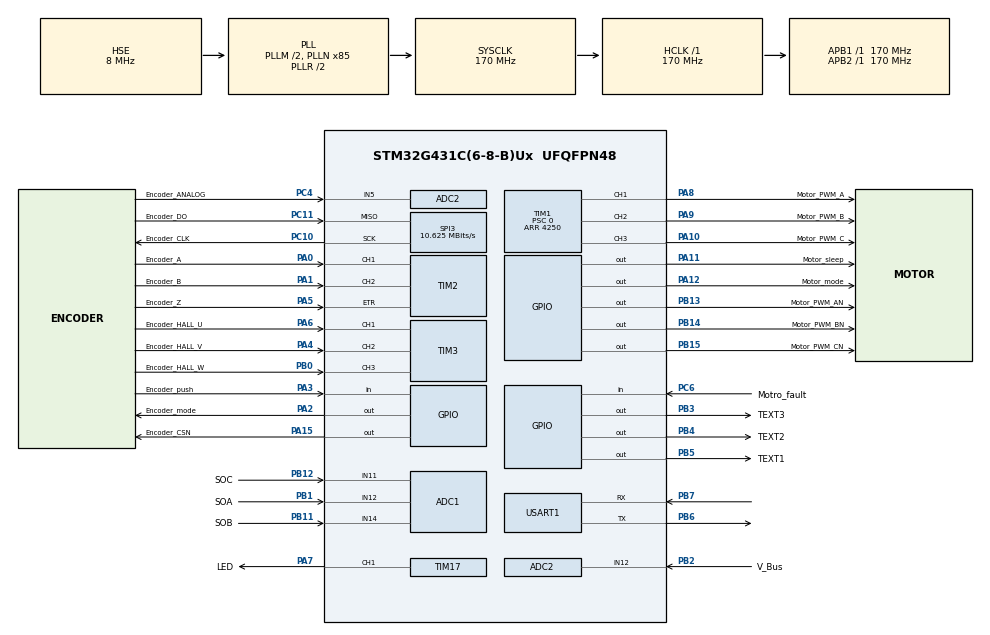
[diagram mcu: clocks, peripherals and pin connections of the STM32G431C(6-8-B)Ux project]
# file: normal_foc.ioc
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ADC1.EnableInjectedConversion=ENABLE
ADC1.EnableRegularConversion=DISABLE
ADC1.ExternalTrigInjecConv=ADC_EXTERNALTRIGINJEC_T1_CC4
ADC1.InjNumberOfConversion=3
ADC1.InjectedChannel-6\#ChannelInjectedConversion=ADC_CHANNEL_12
ADC1.InjectedChannel-7\#ChannelInjectedConversion=ADC_CHANNEL_14
ADC1.InjectedChannel-8\#ChannelInjectedConversion=ADC_CHANNEL_11
ADC1.InjectedOffsetNumber-6\#ChannelInjectedConversion=ADC_OFFSET_NONE
ADC1.InjectedOffsetNumber-7\#ChannelInjectedConversion=ADC_OFFSET_NONE
ADC1.InjectedOffsetNumber-8\#ChannelInjectedConversion=ADC_OFFSET_NONE
ADC1.InjectedRank-6\#ChannelInjectedConversion=1
ADC1.InjectedRank-7\#ChannelInjectedConversion=2
ADC1.InjectedRank-8\#ChannelInjectedConversion=3
ADC1.InjectedSamplingTime-6\#ChannelInjectedConversion=ADC_SAMPLETIME_6CYCLES_5
ADC1.InjectedSamplingTime-7\#ChannelInjectedConversion=ADC_SAMPLETIME_6CYCLES_5
ADC1.InjectedSamplingTime-8\#ChannelInjectedConversion=ADC_SAMPLETIME_6CYCLES_5
ADC1.Rank1_Channel=ADC_CHANNEL_12
ADC1.Rank2_Channel=ADC_CHANNEL_14
ADC1.master=1
ADC2.Channel-7\#ChannelRegularConversion=ADC_CHANNEL_5
ADC2.Channel-8\#ChannelRegularConversion=ADC_CHANNEL_12
ADC2.NbrOfConversion=2
ADC2.NbrOfConversionFlag=1
ADC2.OffsetNumber-7\#ChannelRegularConversion=ADC_OFFSET_NONE
ADC2.OffsetNumber-8\#ChannelRegularConversion=ADC_OFFSET_NONE
ADC2.Rank-7\#ChannelRegularConversion=1
ADC2.Rank-8\#ChannelRegularConversion=2
ADC2.SamplingTime-7\#ChannelRegularConversion=ADC_SAMPLETIME_12CYCLES_5
ADC2.SamplingTime-8\#ChannelRegularConversion=ADC_SAMPLETIME_12CYCLES_5
Dma.Request0=USART1_TX
Dma.Request1=SPI3_RX
Dma.SPI3_RX.1.Direction=DMA_PERIPH_TO_MEMORY
Dma.SPI3_RX.1.EventEnable=DISABLE
Dma.SPI3_RX.1.Instance=DMA1_Channel2
Dma.SPI3_RX.1.MemDataAlignment=DMA_MDATAALIGN_BYTE
Dma.SPI3_RX.1.MemInc=DMA_MINC_ENABLE
Dma.SPI3_RX.1.Mode=DMA_NORMAL
Dma.SPI3_RX.1.PeriphDataAlignment=DMA_PDATAALIGN_BYTE
Dma.SPI3_RX.1.PeriphInc=DMA_PINC_DISABLE
Dma.SPI3_RX.1.Polarity=HAL_DMAMUX_REQ_GEN_RISING
Dma.SPI3_RX.1.Priority=DMA_PRIORITY_LOW
Dma.SPI3_RX.1.RequestNumber=1
Dma.SPI3_RX.1.SignalID=NONE
Dma.SPI3_RX.1.SyncEnable=DISABLE
Dma.SPI3_RX.1.SyncPolarity=HAL_DMAMUX_SYNC_NO_EVENT
Dma.SPI3_RX.1.SyncRequestNumber=1
Dma.SPI3_RX.1.SyncSignalID=NONE
Dma.USART1_TX.0.Direction=DMA_MEMORY_TO_PERIPH
Dma.USART1_TX.0.EventEnable=DISABLE
Dma.USART1_TX.0.Instance=DMA1_Channel1
Dma.USART1_TX.0.MemDataAlignment=DMA_MDATAALIGN_BYTE
Dma.USART1_TX.0.MemInc=DMA_MINC_ENABLE
Dma.USART1_TX.0.Mode=DMA_NORMAL
Dma.USART1_TX.0.PeriphDataAlignment=DMA_PDATAALIGN_BYTE
Dma.USART1_TX.0.PeriphInc=DMA_PINC_DISABLE
Dma.USART1_TX.0.Polarity=HAL_DMAMUX_REQ_GEN_RISING
Dma.USART1_TX.0.Priority=DMA_PRIORITY_LOW
Dma.USART1_TX.0.RequestNumber=1
Dma.USART1_TX.0.SignalID=NONE
Dma.USART1_TX.0.SyncEnable=DISABLE
Dma.USART1_TX.0.SyncPolarity=HAL_DMAMUX_SYNC_NO_EVENT
Dma.USART1_TX.0.SyncRequestNumber=1
Dma.USART1_TX.0.SyncSignalID=NONE
Mcu.Family=STM32G4
Mcu.Name=STM32G431C(6-8-B)Ux
Mcu.Package=UFQFPN48
NVIC.ADC1_2_IRQn=true\:0\:0\:false\:false\:true\:true\:true\:true
NVIC.DMA1_Channel1_IRQn=true\:0\:0\:false\:false\:true\:false\:true\:true
NVIC.DMA1_Channel2_IRQn=true\:0\:0\:false\:false\:true\:false\:true\:true
NVIC.PriorityGroup=NVIC_PRIORITYGROUP_4
NVIC.TIM6_DAC_IRQn=true\:1\:0\:true\:false\:true\:true\:true\:true
NVIC.USART1_IRQn=true\:0\:0\:false\:false\:true\:true\:true\:true
PA0.GPIO_Label=Encoder_A
PA0.Signal=S_TIM2_CH1
PA1.GPIO_Label=Encoder_B
PA1.Signal=S_TIM2_CH2
PA10.GPIO_Label=Motor_PWM_C
PA10.Signal=S_TIM1_CH3
PA11.GPIO_Label=Motor_sleep
PA11.Signal=GPIO_Output
PA12.GPIO_Label=Motor_mode
PA12.Signal=GPIO_Output
PA13.Mode=Serial_Wire
PA13.Signal=SYS_JTMS-SWDIO
PA14.Mode=Serial_Wire
PA14.Signal=SYS_JTCK-SWCLK
PA15.GPIO_Label=Encoder_CSN
PA15.GPIO_PuPd=GPIO_NOPULL
PA15.Signal=GPIO_Output
PA2.GPIO_Label=Encoder_mode
PA2.Signal=GPIO_Output
PA3.GPIO_Label=Encoder_push
PA3.Signal=GPIO_Input
PA4.GPIO_Label=Encoder_HALL_V
PA4.Signal=S_TIM3_CH2
PA5.GPIO_Label=Encoder_Z
PA5.Signal=S_TIM2_ETR
PA6.GPIO_Label=Encoder_HALL_U
PA6.Signal=S_TIM3_CH1
PA7.GPIO_Label=LED
PA7.Signal=S_TIM17_CH1
PA8.GPIO_Label=Motor_PWM_A
PA8.Signal=S_TIM1_CH1
PA9.GPIO_Label=Motor_PWM_B
PA9.Signal=S_TIM1_CH2
PB0.GPIO_Label=Encoder_HALL_W
PB0.Signal=S_TIM3_CH3
PB1.GPIO_Label=SOA
PB1.Mode=IN12-Single-Ended
PB1.Signal=ADC1_IN12
PB11.GPIO_Label=SOB
PB11.Mode=IN14-Single-Ended
PB11.Signal=ADC1_IN14
PB12.GPIO_Label=SOC
PB12.Mode=IN11-Single-Ended
PB12.Signal=ADC1_IN11
PB13.GPIO_Label=Motor_PWM_AN
PB13.Signal=GPIO_Output
PB14.GPIO_Label=Motor_PWM_BN
PB14.Signal=GPIO_Output
PB15.GPIO_Label=Motor_PWM_CN
PB15.Signal=GPIO_Output
PB2.GPIO_Label=V_Bus
PB2.Mode=IN12-Single-Ended
PB2.Signal=ADC2_IN12
PB3.GPIO_Label=TEXT3
PB3.Signal=GPIO_Output
PB4.GPIO_Label=TEXT2
PB4.Signal=GPIO_Output
PB5.GPIO_Label=TEXT1
PB5.Signal=GPIO_Output
PB6.Mode=Asynchronous
PB6.Signal=USART1_TX
PB7.Mode=Asynchronous
PB7.Signal=USART1_RX
PC10.GPIO_Label=Encoder_CLK
PC10.Mode=RX_Only_Simplex_Unidirect_Master
PC10.Signal=SPI3_SCK
PC11.GPIO_Label=Encoder_DO
PC11.Mode=RX_Only_Simplex_Unidirect_Master
PC11.Signal=SPI3_MISO
PC4.GPIO_Label=Encoder_ANALOG
PC4.Mode=IN5-Single-Ended
PC4.Signal=ADC2_IN5
PC6.GPIO_Label=Motro_fault
PC6.Signal=GPIO_Input
PF0-OSC_IN.Mode=HSE-External-Oscillator
PF0-OSC_IN.Signal=RCC_OSC_IN
PF1-OSC_OUT.Mode=HSE-External-Oscillator
PF1-OSC_OUT.Signal=RCC_OSC_OUT
ProjectManager.HeapSize=0x200
ProjectManager.StackSize=0x400
ProjectManager.TargetToolchain=CMake
RCC.ADC12Freq_Value=170000000
RCC.AHBFreq_Value=170000000
RCC.APB1Freq_Value=170000000
RCC.APB1TimFreq_Value=170000000
RCC.APB2Freq_Value=170000000
RCC.APB2TimFreq_Value=170000000
RCC.CortexFreq_Value=170000000
RCC.EXTERNAL_CLOCK_VALUE=12288000
RCC.HCLKFreq_Value=170000000
RCC.HSE_VALUE=8000000
RCC.HSI48_VALUE=48000000
RCC.HSI_VALUE=16000000
RCC.LSE_VALUE=32768
RCC.PLLM=RCC_PLLM_DIV2
RCC.PLLN=85
RCC.PLLSourceVirtual=RCC_PLLSOURCE_HSE
RCC.SYSCLKFreq_VALUE=170000000
RCC.SYSCLKSource=RCC_SYSCLKSOURCE_PLLCLK
RCC.USBFreq_Value=170000000
RCC.VCOOutputFreq_Value=340000000
SH.S_TIM17_CH1.0=TIM17_CH1,PWM Generation1 CH1
SH.S_TIM1_CH1.0=TIM1_CH1,PWM Generation1 CH1
SH.S_TIM1_CH2.0=TIM1_CH2,PWM Generation2 CH2
SH.S_TIM1_CH3.0=TIM1_CH3,PWM Generation3 CH3
SH.S_TIM2_CH1.0=TIM2_CH1,Encoder_Interface_w_index
SH.S_TIM2_CH2.0=TIM2_CH2,Encoder_Interface_w_index
SH.S_TIM2_ETR.0=TIM2_ETR,Encoder_Interface_w_index
SH.S_TIM3_CH1.0=TIM3_CH1,Xored_Inputs_Hall_Sensor_Interface
SH.S_TIM3_CH2.0=TIM3_CH2,Xored_Inputs_Hall_Sensor_Interface
SH.S_TIM3_CH3.0=TIM3_CH3,Xored_Inputs_Hall_Sensor_Interface
SPI3.BaudRatePrescaler=SPI_BAUDRATEPRESCALER_16
SPI3.CLKPhase=SPI_PHASE_1EDGE
SPI3.CLKPolarity=SPI_POLARITY_HIGH
SPI3.CalculateBaudRate=10.625 MBits/s
SPI3.DataSize=SPI_DATASIZE_8BIT
SPI3.Direction=SPI_DIRECTION_2LINES_RXONLY
SPI3.Mode=SPI_MODE_MASTER
SPI3.VirtualType=VM_MASTER
STMicroelectronics.X-CUBE-ALGOBUILD.1.4.0.LibraryCcDSPOoLibraryJjDSPOoLibrary=true
TIM1.Channel-PWM\ Generation1\ CH1=TIM_CHANNEL_1
TIM1.Channel-PWM\ Generation2\ CH2=TIM_CHANNEL_2
TIM1.Channel-PWM\ Generation3\ CH3=TIM_CHANNEL_3
TIM1.Channel-PWM\ Generation4\ No\ Output=TIM_CHANNEL_4
TIM1.CounterMode=TIM_COUNTERMODE_CENTERALIGNED2
TIM1.OCMode_PWM-PWM\ Generation4\ No\ Output=TIM_OCMODE_PWM2
TIM1.PeriodNoDither=4250
TIM1.Prescaler=0
TIM17.Channel=TIM_CHANNEL_1
TIM17.PeriodNoDither=1000
TIM17.Prescaler=169
TIM2.EncoderMode=TIM_ENCODERMODE_TI12
TIM6.PeriodNoDither=1000
TIM6.Prescaler=169
USART1.VirtualMode-Asynchronous=VM_ASYNC
VP_STMicroelectronics.X-CUBE-ALGOBUILD_VS_DSPOoLibraryJjLibrary_1.4.0_1.4.0.Mode=DSPOoLibraryJjLibrary
VP_SYS_VS_DBSignals.Mode=DisableDeadBatterySignals
VP_TIM17_VS_ClockSourceINT.Mode=Enable_Timer
VP_TIM1_VS_no_output4.Mode=PWM Generation4 No Output
VP_TIM6_VS_ClockSourceINT.Mode=Enable_Timer
board=custom

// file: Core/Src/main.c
/* USER CODE BEGIN Header */
/**
  ******************************************************************************
  * @file           : main.c
  * @brief          : Main program body
  ******************************************************************************
  * @attention
  *
  * Copyright (c) 2026 STMicroelectronics.
  * All rights reserved.
  *
  * This software is licensed under terms that can be found in the LICENSE file
  * in the root directory of this software component.
  * If no LICENSE file comes with this software, it is provided AS-IS.
  *
  ******************************************************************************
  */
/* USER CODE END Header */
#include "main.h"
#include "adc.h"
#include "dma.h"
#include "spi.h"
#include "tim.h"
#include "usart.h"
#include "gpio.h"

/* USER CODE BEGIN Includes */
#include "user.h"
/* USER CODE END Includes */

void SystemClock_Config(void);

int main(void)
{

  /* MCU Configuration--------------------------------------------------------*/

  /* Reset of all peripherals, Initializes the Flash interface and the Systick. */
  HAL_Init();

  /* Configure the system clock */
  SystemClock_Config();

  /* Initialize all configured peripherals */
  MX_GPIO_Init();
  MX_DMA_Init();
  MX_ADC1_Init();
  MX_ADC2_Init();
  MX_TIM1_Init();
  MX_TIM2_Init();
  MX_TIM17_Init();
  MX_USART1_UART_Init();
  MX_TIM6_Init();
  MX_SPI3_Init();
  MX_TIM3_Init();

  /* Infinite loop */
  /* USER CODE BEGIN WHILE */
  User_Init();
  while (1)
  {
    User_Loop();
    /* USER CODE END WHILE */

  }
}

void SystemClock_Config(void)
{
  RCC_OscInitTypeDef RCC_OscInitStruct = {0};
  RCC_ClkInitTypeDef RCC_ClkInitStruct = {0};

  /** Configure the main internal regulator output voltage
  */
  HAL_PWREx_ControlVoltageScaling(PWR_REGULATOR_VOLTAGE_SCALE1_BOOST);

  /** Initializes the RCC Oscillators according to the specified parameters
  * in the RCC_OscInitTypeDef structure.
  */
  RCC_OscInitStruct.OscillatorType = RCC_OSCILLATORTYPE_HSE;
  RCC_OscInitStruct.HSEState = RCC_HSE_ON;
  RCC_OscInitStruct.PLL.PLLState = RCC_PLL_ON;
  RCC_OscInitStruct.PLL.PLLSource = RCC_PLLSOURCE_HSE;
  RCC_OscInitStruct.PLL.PLLM = RCC_PLLM_DIV2;
  RCC_OscInitStruct.PLL.PLLN = 85;
  RCC_OscInitStruct.PLL.PLLP = RCC_PLLP_DIV2;
  RCC_OscInitStruct.PLL.PLLQ = RCC_PLLQ_DIV2;
  RCC_OscInitStruct.PLL.PLLR = RCC_PLLR_DIV2;
  if (HAL_RCC_OscConfig(&RCC_OscInitStruct) != HAL_OK)
  {
    Error_Handler();
  }

  /** Initializes the CPU, AHB and APB buses clocks
  */
  RCC_ClkInitStruct.ClockType = RCC_CLOCKTYPE_HCLK|RCC_CLOCKTYPE_SYSCLK
                              |RCC_CLOCKTYPE_PCLK1|RCC_CLOCKTYPE_PCLK2;
  RCC_ClkInitStruct.SYSCLKSource = RCC_SYSCLKSOURCE_PLLCLK;
  RCC_ClkInitStruct.AHBCLKDivider = RCC_SYSCLK_DIV1;
  RCC_ClkInitStruct.APB1CLKDivider = RCC_HCLK_DIV1;
  RCC_ClkInitStruct.APB2CLKDivider = RCC_HCLK_DIV1;

  if (HAL_RCC_ClockConfig(&RCC_ClkInitStruct, FLASH_LATENCY_4) != HAL_OK)
  {
    Error_Handler();
  }
}

void Error_Handler(void)
{
  __disable_irq();
  while (1)
  {
  }
}
